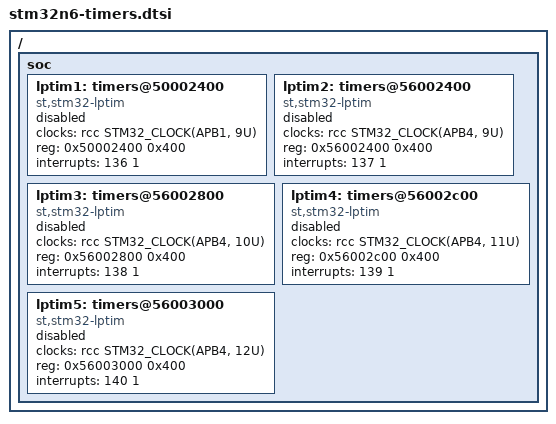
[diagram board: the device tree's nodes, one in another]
/*
 * Copyright (c) 2025 HU Inc.
 *
 * SPDX-License-Identifier: Apache-2.0
 */

#include <arm/armv8.1-m.dtsi>
#include <zephyr/dt-bindings/pwm/pwm.h>
#include <zephyr/dt-bindings/pwm/stm32_pwm.h>
#include <zephyr/dt-bindings/clock/stm32n6_clock.h>
#include <zephyr/dt-bindings/reset/stm32n6_reset.h>
#include <zephyr/dt-bindings/sensor/qdec_stm32.h>
#include <freq.h>

/ {
	soc {
		lptim1: timers@50002400 {
			compatible = "st,stm32-lptim";
			clocks = <&rcc STM32_CLOCK(APB1, 9U)>;
			#address-cells = <1>;	/* SEL: 8U */
			#size-cells = <0>;
			reg = <0x50002400 0x400>;
			interrupts = <136 1>;
			interrupt-names = "global";
			status = "disabled";
		};
		lptim2: timers@56002400 {
			compatible = "st,stm32-lptim";
			clocks = <&rcc STM32_CLOCK(APB4, 9U)>;
			#address-cells = <1>;	/* SEL: 12U */
			#size-cells = <0>;
			reg = <0x56002400 0x400>;
			interrupts = <137 1>;
			interrupt-names = "global";
			status = "disabled";
		};
		lptim3: timers@56002800 {
			compatible = "st,stm32-lptim";
			clocks = <&rcc STM32_CLOCK(APB4, 10U)>;
			#address-cells = <1>;	/* SEL: 16U */
			#size-cells = <0>;
			reg = <0x56002800 0x400>;
			interrupts = <138 1>;
			interrupt-names = "global";
			status = "disabled";
		};
		lptim4: timers@56002c00 {
			compatible = "st,stm32-lptim";
			clocks = <&rcc STM32_CLOCK(APB4, 11U)>;
			#address-cells = <1>;	/* SEL: 20U */
			#size-cells = <0>;
			reg = <0x56002c00 0x400>;
			interrupts = <139 1>;
			interrupt-names = "global";
			status = "disabled";
		};
		lptim5: timers@56003000 {
			compatible = "st,stm32-lptim";
			clocks = <&rcc STM32_CLOCK(APB4, 12U)>;
			#address-cells = <1>;	/* SEL: 24U */
			#size-cells = <0>;
			reg = <0x56003000 0x400>;
			interrupts = <140 1>;
			interrupt-names = "global";
			status = "disabled";
		};
	};
};
